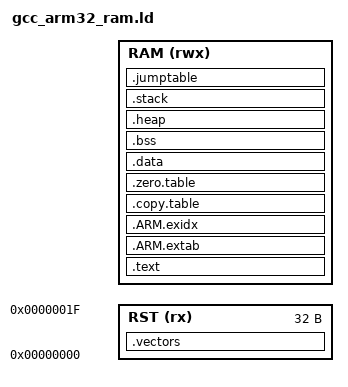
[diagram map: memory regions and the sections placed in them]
MEMORY
{
  RST  (rx)  : ORIGIN = 0x00000000, LENGTH = 0x20
  RAM  (rwx) : ORIGIN = __RAM_BASE, LENGTH = __RAM_SIZE
}

ASSERT(__JUMPTABLE_BASE <= __RAM_BASE + __RAM_SIZE, "jumptable exists after RAM")

ENTRY(_reset)

SECTIONS
{
  .vectors :
  {
    KEEP(*(.vectors))
  } > RST

  .text :
  {
    *(.text*)

    KEEP(*(.init))
    KEEP(*(.fini))

    /* .ctors */
    *crtbegin.o(.ctors)
    *crtbegin?.o(.ctors)
    *(EXCLUDE_FILE(*crtend?.o *crtend.o) .ctors)
    *(SORT(.ctors.*))
    *(.ctors)

    /* .dtors */
    *crtbegin.o(.dtors)
    *crtbegin?.o(.dtors)
    *(EXCLUDE_FILE(*crtend?.o *crtend.o) .dtors)
    *(SORT(.dtors.*))
    *(.dtors)

    *(.rodata*)

    KEEP(*(.eh_frame*))
  } > RAM

  .ARM.extab :
  {
    *(.ARM.extab* .gnu.linkonce.armextab.*)
  } > RAM

  __exidx_start = .;
  .ARM.exidx :
  {
    *(.ARM.exidx* .gnu.linkonce.armexidx.*)
  } > RAM
  __exidx_end = .;

  .copy.table :
  {
    . = ALIGN(4);
    __copy_table_start__ = .;
    LONG (__etext)
    LONG (__data_start__)
    LONG (__data_end__ - __data_start__)
    __copy_table_end__ = .;
  } > RAM

  .zero.table :
  {
    . = ALIGN(4);
    __zero_table_start__ = .;
    __zero_table_end__ = .;
  } > RAM

  __etext = ALIGN (4);

  .data : AT (__etext)
  {
    __data_start__ = .;
    *(vtable)
    *(.data)
    *(.data.*)

    . = ALIGN(4);
    /* preinit data */
    PROVIDE_HIDDEN (__preinit_array_start = .);
    KEEP(*(.preinit_array))
    PROVIDE_HIDDEN (__preinit_array_end = .);

    . = ALIGN(4);
    /* init data */
    PROVIDE_HIDDEN (__init_array_start = .);
    KEEP(*(SORT(.init_array.*)))
    KEEP(*(.init_array))
    PROVIDE_HIDDEN (__init_array_end = .);

    . = ALIGN(4);
    /* finit data */
    PROVIDE_HIDDEN (__fini_array_start = .);
    KEEP(*(SORT(.fini_array.*)))
    KEEP(*(.fini_array))
    PROVIDE_HIDDEN (__fini_array_end = .);

    KEEP(*(.jcr*))
    . = ALIGN(4);
    /* All data end */
    __data_end__ = .;

  } > RAM

  .bss :
  {
    . = ALIGN(4);
    __bss_start__ = .;
    *(.bss)
    *(.bss.*)
    *(COMMON)
    . = ALIGN(4);
    __bss_end__ = .;
  } > RAM

  .heap (NOLOAD) :
  {
    . = ALIGN(8);
    __end__ = .;
    PROVIDE(end = .);
    . = . + __HEAP_SIZE;
    . = ALIGN(8);
    __HeapLimit = .;
  } > RAM

  .stack (__JUMPTABLE_BASE - __STACK_SIZE - 8) (NOLOAD) :
  {
    . = ALIGN(8);
    __StackLimit = .;
    . = . + __STACK_SIZE;
    . = ALIGN(8);
    __StackTop = .;
    __stack = .;
  } > RAM

  /* Check if data + heap + stack exceeds RAM limit */
  ASSERT(__StackLimit >= __HeapLimit, "region RAM overflowed with stack")

  .jumptable (__JUMPTABLE_BASE) :
  {
    KEEP(*(.jumptable))
  } > RAM
}
